VERSION ""

NS_ :

BS_:

BU_: INERTIAL_MEASUREMENT_UNIT

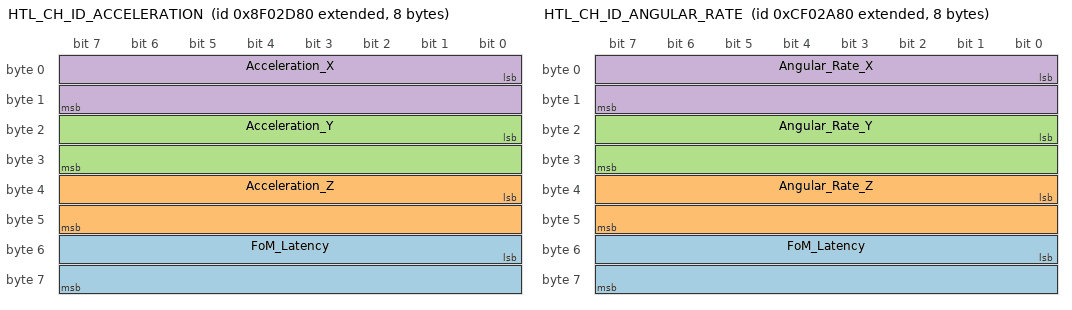
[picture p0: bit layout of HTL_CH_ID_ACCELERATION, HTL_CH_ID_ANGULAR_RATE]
BO_ 2297441664 HTL_CH_ID_ACCELERATION: 8 INERTIAL_MEASUREMENT_UNIT
 SG_ FoM_Latency : 48|16@1+ (1,0) [0|65535] "" Vector__XXX
 SG_ Acceleration_Z : 32|16@1- (0.01,-320) [-320|5.81818181818182] "m/s^2" Vector__XXX
 SG_ Acceleration_Y : 16|16@1- (0.01,-320) [-320|5.81818181818182] "m/s^2" Vector__XXX
 SG_ Acceleration_X : 0|16@1- (0.01,-320) [-320|5.81818181818182] "m/s^2" Vector__XXX

BO_ 2364549760 HTL_CH_ID_ANGULAR_RATE: 8 INERTIAL_MEASUREMENT_UNIT
 SG_ FoM_Latency : 48|16@1+ (1,0) [0|65535] "" Vector__XXX
 SG_ Angular_Rate_Z : 32|16@1- (0.0078125,-250) [-250|252] "deg/s" Vector__XXX
 SG_ Angular_Rate_Y : 16|16@1- (0.0078125,-250) [-250|252] "deg/s" Vector__XXX
 SG_ Angular_Rate_X : 0|16@1- (0.0078125,-250) [-250|252] "deg/s" Vector__XXX

BA_DEF_  "MultiplexExtEnabled" ENUM  "No","Yes";
BA_DEF_  "BusType" STRING ;
BA_DEF_DEF_  "MultiplexExtEnabled" "No";
BA_DEF_DEF_  "BusType" "CAN";
BA_ "MultiplexExtEnabled" 1;
